AUTOSAR XML (schema 00046)
package /TigerDetectionSW
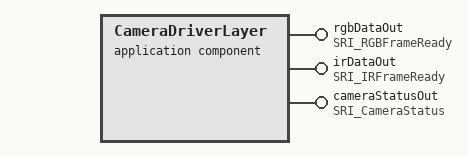
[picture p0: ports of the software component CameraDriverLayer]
  application sw component type CameraDriverLayer
    provide port rgbDataOut: provided-interface=SRI_RGBFrameReady
    provide port irDataOut: provided-interface=SRI_IRFrameReady
    provide port cameraStatusOut: provided-interface=SRI_CameraStatus
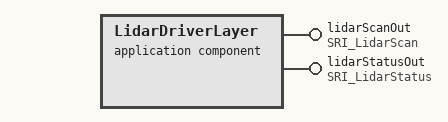
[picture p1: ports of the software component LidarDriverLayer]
  application sw component type LidarDriverLayer
    provide port lidarScanOut: provided-interface=SRI_LidarScan
    provide port lidarStatusOut: provided-interface=SRI_LidarStatus
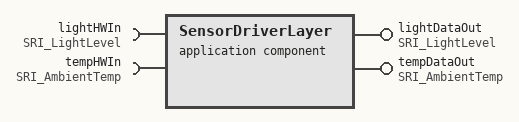
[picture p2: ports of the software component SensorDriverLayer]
  application sw component type SensorDriverLayer
    provide port lightDataOut: provided-interface=SRI_LightLevel
    provide port tempDataOut: provided-interface=SRI_AmbientTemp
    require port lightHWIn: required-interface=SRI_LightLevel
    require port tempHWIn: required-interface=SRI_AmbientTemp
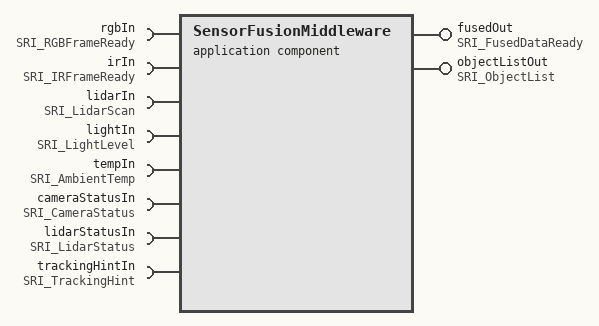
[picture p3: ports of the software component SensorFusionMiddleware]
  application sw component type SensorFusionMiddleware
    provide port fusedOut: provided-interface=SRI_FusedDataReady
    provide port objectListOut: provided-interface=SRI_ObjectList
    8 x require port:
      rgbIn: required-interface=SRI_RGBFrameReady
      irIn: required-interface=SRI_IRFrameReady
      lidarIn: required-interface=SRI_LidarScan
      lightIn: required-interface=SRI_LightLevel
      tempIn: required-interface=SRI_AmbientTemp
      cameraStatusIn: required-interface=SRI_CameraStatus
      lidarStatusIn: required-interface=SRI_LidarStatus
      trackingHintIn: required-interface=SRI_TrackingHint
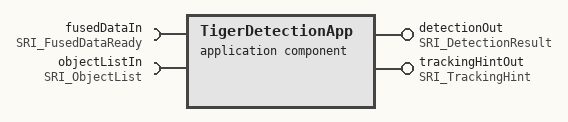
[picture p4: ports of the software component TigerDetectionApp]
  application sw component type TigerDetectionApp
    provide port detectionOut: provided-interface=SRI_DetectionResult
    provide port trackingHintOut: provided-interface=SRI_TrackingHint
    require port fusedDataIn: required-interface=SRI_FusedDataReady
    require port objectListIn: required-interface=SRI_ObjectList
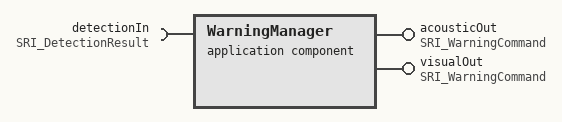
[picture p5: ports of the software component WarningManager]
  application sw component type WarningManager
    provide port acousticOut: provided-interface=SRI_WarningCommand
    provide port visualOut: provided-interface=SRI_WarningCommand
    require port detectionIn: required-interface=SRI_DetectionResult
  composition sw component type TigerDetectionComposition
    6 x component:
      CameraDriverLayer_Instance: type=CameraDriverLayer
      LidarDriverLayer_Instance: type=LidarDriverLayer
      SensorDriverLayer_Instance: type=SensorDriverLayer
      SensorFusionMiddleware_Instance: type=SensorFusionMiddleware
      TigerDetectionApp_Instance: type=TigerDetectionApp
      WarningManager_Instance: type=WarningManager
    connect CameraDriverLayer_Instance.rgbDataOut -> SensorFusionMiddleware_Instance.rgbIn
    connect CameraDriverLayer_Instance.irDataOut -> SensorFusionMiddleware_Instance.irIn
    connect CameraDriverLayer_Instance.cameraStatusOut -> SensorFusionMiddleware_Instance.cameraStatusIn
    connect LidarDriverLayer_Instance.lidarScanOut -> SensorFusionMiddleware_Instance.lidarIn
    connect LidarDriverLayer_Instance.lidarStatusOut -> SensorFusionMiddleware_Instance.lidarStatusIn
    connect SensorDriverLayer_Instance.lightDataOut -> SensorFusionMiddleware_Instance.lightIn
    connect SensorDriverLayer_Instance.tempDataOut -> SensorFusionMiddleware_Instance.tempIn
    connect SensorFusionMiddleware_Instance.fusedOut -> TigerDetectionApp_Instance.fusedDataIn
    connect SensorFusionMiddleware_Instance.objectListOut -> TigerDetectionApp_Instance.objectListIn
    connect TigerDetectionApp_Instance.detectionOut -> WarningManager_Instance.detectionIn
    connect TigerDetectionApp_Instance.trackingHintOut -> SensorFusionMiddleware_Instance.trackingHintIn
